VERSION ""

NS_ :

BS_:

BU_:

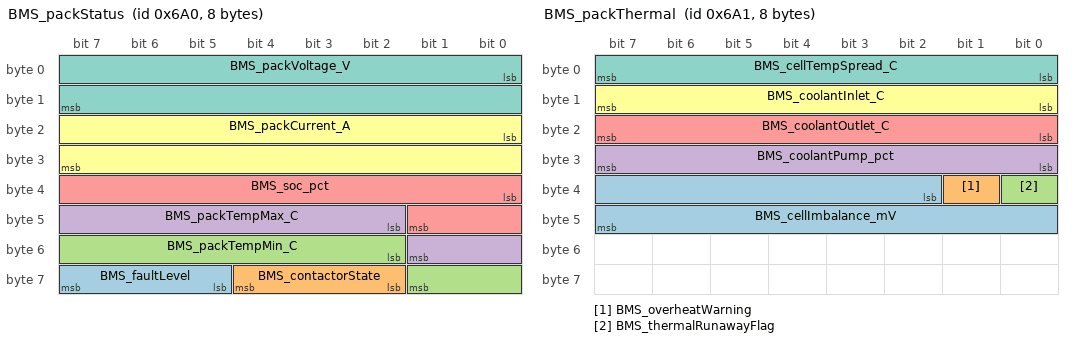
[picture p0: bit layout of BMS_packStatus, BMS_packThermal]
BO_ 1696 BMS_packStatus: 8 BMS
 SG_ BMS_faultLevel : 61|3@1+ (1,0) [0|0] "" Vector__XXX
 SG_ BMS_contactorState : 58|3@1+ (1,0) [0|0] "" Vector__XXX
 SG_ BMS_packTempMin_C : 50|8@1+ (1,-40) [-40|125] "C" Vector__XXX
 SG_ BMS_packTempMax_C : 42|8@1+ (1,-40) [-40|125] "C" Vector__XXX
 SG_ BMS_soc_pct : 32|10@1+ (0.1,0) [0|100] "%" Vector__XXX
 SG_ BMS_packCurrent_A : 16|16@1- (0.1,-500) [-500|500] "A" Vector__XXX
 SG_ BMS_packVoltage_V : 0|16@1+ (0.1,0) [0|800] "V" Vector__XXX

BO_ 1697 BMS_packThermal: 8 BMS
 SG_ BMS_cellImbalance_mV : 34|14@1+ (1,0) [0|16383] "mV" Vector__XXX
 SG_ BMS_overheatWarning : 33|1@1+ (1,0) [0|0] "" Vector__XXX
 SG_ BMS_thermalRunawayFlag : 32|1@1+ (1,0) [0|0] "" Vector__XXX
 SG_ BMS_coolantPump_pct : 24|8@1+ (0.5,0) [0|100] "%" Vector__XXX
 SG_ BMS_coolantOutlet_C : 16|8@1+ (1,-40) [-40|125] "C" Vector__XXX
 SG_ BMS_coolantInlet_C : 8|8@1+ (1,-40) [-40|125] "C" Vector__XXX
 SG_ BMS_cellTempSpread_C : 0|8@1+ (0.5,0) [0|60] "C" Vector__XXX

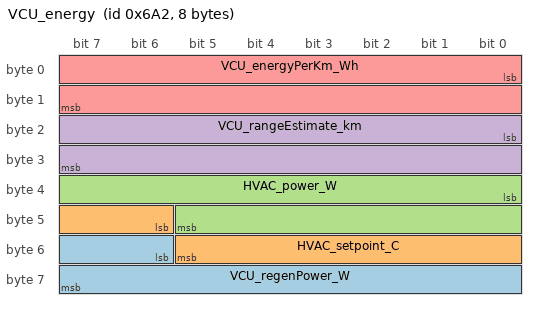
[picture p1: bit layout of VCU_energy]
BO_ 1698 VCU_energy: 8 VCU
 SG_ VCU_regenPower_W : 54|10@1+ (100,0) [0|102300] "W" Vector__XXX
 SG_ HVAC_setpoint_C : 46|8@1+ (0.5,0) [0|60] "C" Vector__XXX
 SG_ HVAC_power_W : 32|14@1+ (5,0) [0|8000] "W" Vector__XXX
 SG_ VCU_rangeEstimate_km : 16|16@1+ (0.1,0) [0|1000] "km" Vector__XXX
 SG_ VCU_energyPerKm_Wh : 0|16@1+ (0.5,0) [0|2000] "Wh/km" Vector__XXX
